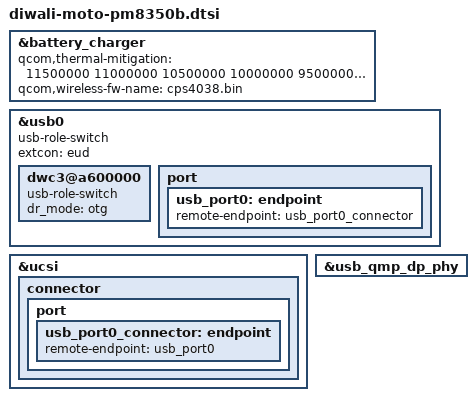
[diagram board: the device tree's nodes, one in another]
/* Copyright (c) 2022, The Linux Foundation. All rights reserved.
 *
 * This program is free software; you can redistribute it and/or modify
 * it under the terms of the GNU General Public License version 2 and
 * only version 2 as published by the Free Software Foundation.
 *
 * This program is distributed in the hope that it will be useful,
 * but WITHOUT ANY WARRANTY; without even the implied warranty of
 * MERCHANTABILITY or FITNESS FOR A PARTICULAR PURPOSE.  See the
 * GNU General Public License for more details.
 */

/*
   This base is original from "diwali-qrd-pm7250b.dtsi"
*/

#include "diwali-pm8350b.dtsi"

&battery_charger {
	qcom,thermal-mitigation = <11500000 11000000 10500000 10000000 9500000
				9000000 8500000 8000000 7500000 7000000 6500000
				6000000 5500000 5000000 4500000 4000000 3500000
				3000000 2500000 2000000 1500000 1000000 500000>;
	qcom,wireless-fw-name = "cps4038.bin";
};

&usb0 {
	usb-role-switch;
	extcon = <&eud>;

	dwc3@a600000 {
		usb-role-switch;
		dr_mode = "otg";
	};

	port {
		usb_port0: endpoint {
			remote-endpoint = <&usb_port0_connector>;
		};
	};
};

&ucsi {
	connector {
		port {
			usb_port0_connector: endpoint {
				remote-endpoint = <&usb_port0>;
			};
		};
	};
};

&usb_qmp_dp_phy {
	pinctrl-names = "unused";
};
